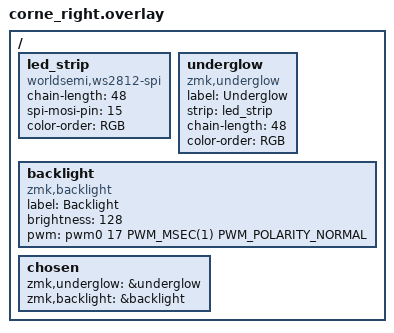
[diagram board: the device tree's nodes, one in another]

/ {

    led_strip: led_strip {
        compatible = "worldsemi,ws2812-spi"; // More reliable than PWM
        chain-length = <48>; // Number of LEDs
        spi-mosi-pin = <15>; // P0.15 (commonly used for LED strips)
        color-order = "RGB"; // Try "GRB" if colors are wrong
    };

    underglow {
        compatible = "zmk,underglow";
        label = "Underglow";
        strip = <&led_strip>;
        chain-length = <48>; // Change to the number of LEDs you have
        color-order = <RGB>; // Or GRB depending on your LED type
    };

    backlight {
        compatible = "zmk,backlight";
        label = "Backlight";
        brightness = <128>;
        pwm = <&pwm0 17 PWM_MSEC(1) PWM_POLARITY_NORMAL>; // Change pin if needed
    };

    chosen {
        zmk,underglow = &underglow;
        zmk,backlight = &backlight;
    };
};
